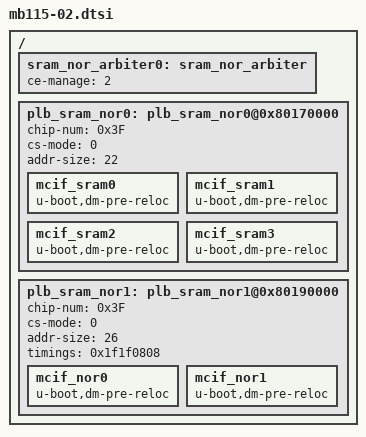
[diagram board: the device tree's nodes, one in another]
/*
 * Device Tree Source for RCM MB115-02 board (SRAM, NOR)
 *
 * This file is licensed under the terms of the GNU General Public
 * License version 2.  This program is licensed "as is" without
 * any warranty of any kind, whether express or implied.
 */

/ {
	sram_nor_arbiter0: sram_nor_arbiter {
		ce-manage = <2>;         // LSIF: all cs=>1 controller, cs-mode=1, chip-num=0x10
	};

	plb_sram_nor0: plb_sram_nor0@0x80170000 {
		status = "okay";
		chip-num = <0x3F>;
		cs-mode = <0>;  // 0 - cs in address, 1 - cs in reg
		addr-size = <22>;  // min 10 max 26 bit
		mcif_sram0: mcif_sram0 {
			u-boot,dm-pre-reloc;
			ranges = <0xc0000000 0x4 0x00000000 0x01000000>;
		};
		mcif_sram1: mcif_sram1 {
			u-boot,dm-pre-reloc;
			ranges = <0xc1000000 0x4 0x01000000 0x01000000>;
		};
		mcif_sram2: mcif_sram2 {
			u-boot,dm-pre-reloc;
			ranges = <0xc2000000 0x4 0x02000000 0x01000000>;
		};
		mcif_sram3: mcif_sram3 {
			u-boot,dm-pre-reloc;
			ranges = <0xc3000000 0x4 0x03000000 0x01000000>;
		};
	};

	plb_sram_nor1: plb_sram_nor1@0x80190000 {
		status = "okay";
		chip-num = <0x3F>;
		cs-mode = <0>;  // 0 - cs in address, 1 - cs in reg
		addr-size = <26>;  // min 10 max 26 bit
		timings = <0x1f1f0808>;
		mcif_nor0: mcif_nor0 {
			u-boot,dm-pre-reloc;
			ranges = <0x20000000 0x6 0x00000000 0x10000000>;
		};
		mcif_nor1: mcif_nor1 {
			u-boot,dm-pre-reloc;
			ranges = <0x10000000 0x6 0x10000000 0x10000000>;
		};
	};
};
